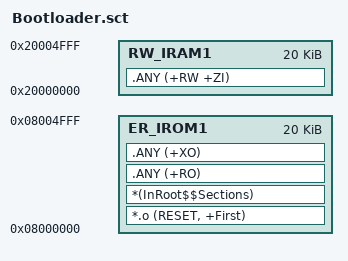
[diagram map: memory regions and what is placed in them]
; *************************************************************
; *** Bootloader 散列文件 - IROM 限制 20KB (0x08000000~0x08004FFF) ***
; *************************************************************

LR_IROM1 0x08000000 0x00005000  {
  ER_IROM1 0x08000000 0x00005000  {
   *.o (RESET, +First)
   *(InRoot$$Sections)
   .ANY (+RO)
   .ANY (+XO)
  }
  RW_IRAM1 0x20000000 0x00005000  {
   .ANY (+RW +ZI)
  }
}
